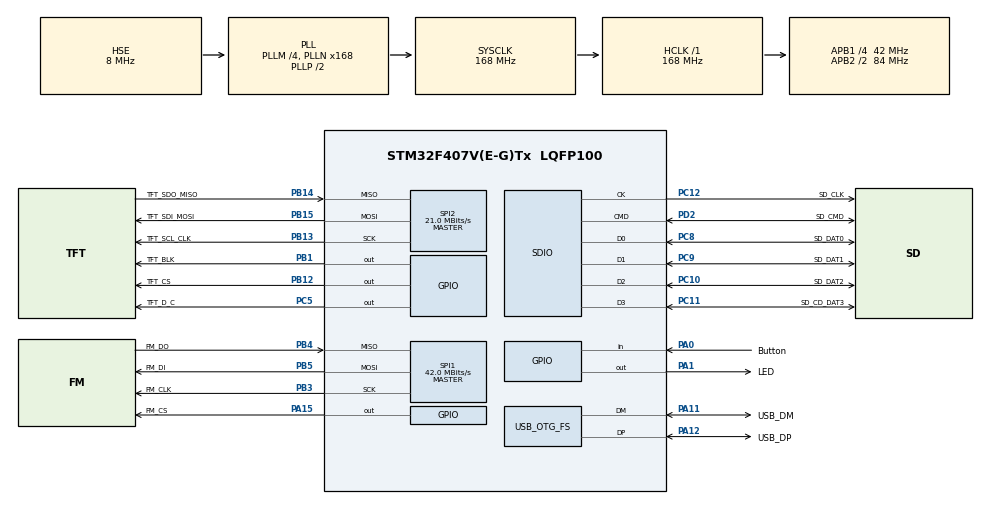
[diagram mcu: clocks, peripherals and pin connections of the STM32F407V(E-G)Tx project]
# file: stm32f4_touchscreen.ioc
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FREERTOS.Tasks01=defaultTask,24,128,StartDefaultTask,Default,NULL,Dynamic,NULL,NULL;blink_led,8,128,Blink,Default,NULL,Dynamic,NULL,NULL
FREERTOS.configUSE_NEWLIB_REENTRANT=1
Mcu.Family=STM32F4
Mcu.Name=STM32F407V(E-G)Tx
Mcu.Package=LQFP100
NVIC.OTG_FS_IRQn=true\:5\:0\:false\:false\:true\:true\:true\:true\:true
NVIC.PriorityGroup=NVIC_PRIORITYGROUP_4
NVIC.SDIO_IRQn=true\:5\:0\:false\:false\:true\:true\:true\:true\:true
PA0-WKUP.GPIO_Label=Button
PA0-WKUP.GPIO_PuPd=GPIO_PULLDOWN
PA0-WKUP.Signal=GPIO_Input
PA1.GPIO_Label=LED
PA1.GPIO_PuPd=GPIO_PULLUP
PA1.Signal=GPIO_Output
PA11.GPIO_Label=USB_DM
PA11.Mode=Device_Only
PA11.Signal=USB_OTG_FS_DM
PA12.GPIO_Label=USB_DP
PA12.Mode=Device_Only
PA12.Signal=USB_OTG_FS_DP
PA13.Mode=Serial_Wire
PA13.Signal=SYS_JTMS-SWDIO
PA14.Mode=Serial_Wire
PA14.Signal=SYS_JTCK-SWCLK
PA15.GPIO_Label=FM_CS
PA15.GPIO_PuPd=GPIO_PULLDOWN
PA15.GPIO_Speed=GPIO_SPEED_FREQ_VERY_HIGH
PA15.Signal=GPIO_Output
PB1.GPIO_Label=TFT_BLK
PB1.GPIO_PuPd=GPIO_PULLDOWN
PB1.GPIO_Speed=GPIO_SPEED_FREQ_VERY_HIGH
PB1.Signal=GPIO_Output
PB12.GPIO_Label=TFT_CS
PB12.GPIO_PuPd=GPIO_PULLDOWN
PB12.GPIO_Speed=GPIO_SPEED_FREQ_VERY_HIGH
PB12.Signal=GPIO_Output
PB13.GPIO_Label=TFT_SCL_CLK
PB13.Mode=Full_Duplex_Master
PB13.Signal=SPI2_SCK
PB14.GPIO_Label=TFT_SDO_MISO
PB14.Mode=Full_Duplex_Master
PB14.Signal=SPI2_MISO
PB15.GPIO_Label=TFT_SDI_MOSI
PB15.Mode=Full_Duplex_Master
PB15.Signal=SPI2_MOSI
PB3.GPIO_Label=FM_CLK
PB3.Mode=Full_Duplex_Master
PB3.Signal=SPI1_SCK
PB4.GPIO_Label=FM_DO
PB4.Mode=Full_Duplex_Master
PB4.Signal=SPI1_MISO
PB5.GPIO_Label=FM_DI
PB5.Mode=Full_Duplex_Master
PB5.Signal=SPI1_MOSI
PC10.GPIO_Label=SD_DAT2
PC10.Mode=SD_4_bits_Wide_bus
PC10.Signal=SDIO_D2
PC11.GPIO_Label=SD_CD_DAT3
PC11.Mode=SD_4_bits_Wide_bus
PC11.Signal=SDIO_D3
PC12.GPIO_Label=SD_CLK
PC12.Mode=SD_4_bits_Wide_bus
PC12.Signal=SDIO_CK
PC14-OSC32_IN.Mode=LSE-External-Oscillator
PC14-OSC32_IN.Signal=RCC_OSC32_IN
PC15-OSC32_OUT.Mode=LSE-External-Oscillator
PC15-OSC32_OUT.Signal=RCC_OSC32_OUT
PC5.GPIO_Label=TFT_D_C
PC5.GPIO_PuPd=GPIO_PULLDOWN
PC5.GPIO_Speed=GPIO_SPEED_FREQ_VERY_HIGH
PC5.Signal=GPIO_Output
PC8.GPIO_Label=SD_DAT0
PC8.Mode=SD_4_bits_Wide_bus
PC8.Signal=SDIO_D0
PC9.GPIO_Label=SD_DAT1
PC9.Mode=SD_4_bits_Wide_bus
PC9.Signal=SDIO_D1
PD2.GPIO_Label=SD_CMD
PD2.Mode=SD_4_bits_Wide_bus
PD2.Signal=SDIO_CMD
PH0-OSC_IN.Mode=HSE-External-Oscillator
PH0-OSC_IN.Signal=RCC_OSC_IN
PH1-OSC_OUT.Mode=HSE-External-Oscillator
PH1-OSC_OUT.Signal=RCC_OSC_OUT
ProjectManager.HeapSize=0x600
ProjectManager.StackSize=0x800
ProjectManager.TargetToolchain=STM32CubeIDE
RCC.48MHZClocksFreq_Value=48000000
RCC.AHBFreq_Value=168000000
RCC.APB1CLKDivider=RCC_HCLK_DIV4
RCC.APB1Freq_Value=42000000
RCC.APB1TimFreq_Value=84000000
RCC.APB2CLKDivider=RCC_HCLK_DIV2
RCC.APB2Freq_Value=84000000
RCC.APB2TimFreq_Value=168000000
RCC.CortexFreq_Value=168000000
RCC.HCLKFreq_Value=168000000
RCC.HSE_VALUE=8000000
RCC.HSI_VALUE=16000000
RCC.PLLM=4
RCC.PLLN=168
RCC.PLLQ=7
RCC.SYSCLKFreq_VALUE=168000000
RCC.SYSCLKSource=RCC_SYSCLKSOURCE_PLLCLK
RCC.VCOOutputFreq_Value=336000000
SPI1.CalculateBaudRate=42.0 MBits/s
SPI1.Direction=SPI_DIRECTION_2LINES
SPI1.Mode=SPI_MODE_MASTER
SPI1.VirtualType=VM_MASTER
SPI2.CalculateBaudRate=21.0 MBits/s
SPI2.Direction=SPI_DIRECTION_2LINES
SPI2.Mode=SPI_MODE_MASTER
SPI2.VirtualType=VM_MASTER
USB_DEVICE.CLASS_NAME_FS=CDC
USB_DEVICE.VirtualMode-CDC_FS=Cdc
USB_DEVICE.VirtualModeFS=Cdc_FS
USB_OTG_FS.VirtualMode=Device_Only
VP_FATFS_VS_SDIO.Mode=SDIO
VP_FREERTOS_VS_CMSIS_V2.Mode=CMSIS_V2
VP_USB_DEVICE_VS_USB_DEVICE_CDC_FS.Mode=CDC_FS
board=custom

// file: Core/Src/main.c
/* USER CODE BEGIN Header */
/**
  ******************************************************************************
  * @file           : main.c
  * @brief          : Main program body
  ******************************************************************************
  * @attention
  *
  * Copyright (c) 2023 STMicroelectronics.
  * All rights reserved.
  *
  * This software is licensed under terms that can be found in the LICENSE file
  * in the root directory of this software component.
  * If no LICENSE file comes with this software, it is provided AS-IS.
  *
  ******************************************************************************
  */
/* USER CODE END Header */
#include "main.h"
#include "cmsis_os.h"
#include "fatfs.h"
#include "usb_device.h"

/* USER CODE BEGIN Includes */
#include <stdio.h>
#include "usbd_cdc_if.h"
/* USER CODE END Includes */

SD_HandleTypeDef hsd;

SPI_HandleTypeDef hspi1;
SPI_HandleTypeDef hspi2;

/* Definitions for defaultTask */
osThreadId_t defaultTaskHandle;
const osThreadAttr_t defaultTask_attributes = {
  .name = "defaultTask",
  .stack_size = 128 * 4,
  .priority = (osPriority_t) osPriorityNormal,
};
/* Definitions for blink_led */
osThreadId_t blink_ledHandle;
const osThreadAttr_t blink_led_attributes = {
  .name = "blink_led",
  .stack_size = 128 * 4,
  .priority = (osPriority_t) osPriorityLow,
};

void SystemClock_Config(void);
static void MX_GPIO_Init(void);
static void MX_SDIO_SD_Init(void);
static void MX_SPI1_Init(void);
static void MX_SPI2_Init(void);
void StartDefaultTask(void *argument);
void Blink(void *argument);

int main(void)
{

  /* MCU Configuration--------------------------------------------------------*/

  /* Reset of all peripherals, Initializes the Flash interface and the Systick. */
  HAL_Init();

  /* Configure the system clock */
  SystemClock_Config();

  /* Initialize all configured peripherals */
  MX_GPIO_Init();
  MX_SDIO_SD_Init();
  MX_SPI1_Init();
  MX_SPI2_Init();
  MX_FATFS_Init();

  /* Init scheduler */
  osKernelInitialize();

  /* Create the thread(s) */
  /* creation of defaultTask */
  defaultTaskHandle = osThreadNew(StartDefaultTask, NULL, &defaultTask_attributes);

  /* creation of blink_led */
  blink_ledHandle = osThreadNew(Blink, NULL, &blink_led_attributes);

  /* Start scheduler */
  osKernelStart();

  /* We should never get here as control is now taken by the scheduler */
  /* Infinite loop */
  while (1)
  {

  }
}

void SystemClock_Config(void)
{
  RCC_OscInitTypeDef RCC_OscInitStruct = {0};
  RCC_ClkInitTypeDef RCC_ClkInitStruct = {0};

  /** Configure the main internal regulator output voltage
  */
  __HAL_RCC_PWR_CLK_ENABLE();
  __HAL_PWR_VOLTAGESCALING_CONFIG(PWR_REGULATOR_VOLTAGE_SCALE1);

  /** Initializes the RCC Oscillators according to the specified parameters
  * in the RCC_OscInitTypeDef structure.
  */
  RCC_OscInitStruct.OscillatorType = RCC_OSCILLATORTYPE_HSE;
  RCC_OscInitStruct.HSEState = RCC_HSE_ON;
  RCC_OscInitStruct.PLL.PLLState = RCC_PLL_ON;
  RCC_OscInitStruct.PLL.PLLSource = RCC_PLLSOURCE_HSE;
  RCC_OscInitStruct.PLL.PLLM = 4;
  RCC_OscInitStruct.PLL.PLLN = 168;
  RCC_OscInitStruct.PLL.PLLP = RCC_PLLP_DIV2;
  RCC_OscInitStruct.PLL.PLLQ = 7;
  if (HAL_RCC_OscConfig(&RCC_OscInitStruct) != HAL_OK)
  {
    Error_Handler();
  }

  /** Initializes the CPU, AHB and APB buses clocks
  */
  RCC_ClkInitStruct.ClockType = RCC_CLOCKTYPE_HCLK|RCC_CLOCKTYPE_SYSCLK
                              |RCC_CLOCKTYPE_PCLK1|RCC_CLOCKTYPE_PCLK2;
  RCC_ClkInitStruct.SYSCLKSource = RCC_SYSCLKSOURCE_PLLCLK;
  RCC_ClkInitStruct.AHBCLKDivider = RCC_SYSCLK_DIV1;
  RCC_ClkInitStruct.APB1CLKDivider = RCC_HCLK_DIV4;
  RCC_ClkInitStruct.APB2CLKDivider = RCC_HCLK_DIV2;

  if (HAL_RCC_ClockConfig(&RCC_ClkInitStruct, FLASH_LATENCY_5) != HAL_OK)
  {
    Error_Handler();
  }
}

static void MX_SDIO_SD_Init(void)
{

  hsd.Instance = SDIO;
  hsd.Init.ClockEdge = SDIO_CLOCK_EDGE_RISING;
  hsd.Init.ClockBypass = SDIO_CLOCK_BYPASS_DISABLE;
  hsd.Init.ClockPowerSave = SDIO_CLOCK_POWER_SAVE_DISABLE;
  hsd.Init.BusWide = SDIO_BUS_WIDE_4B;
  hsd.Init.HardwareFlowControl = SDIO_HARDWARE_FLOW_CONTROL_DISABLE;
  hsd.Init.ClockDiv = 0;

}

static void MX_SPI1_Init(void)
{

  /* SPI1 parameter configuration*/
  hspi1.Instance = SPI1;
  hspi1.Init.Mode = SPI_MODE_MASTER;
  hspi1.Init.Direction = SPI_DIRECTION_2LINES;
  hspi1.Init.DataSize = SPI_DATASIZE_8BIT;
  hspi1.Init.CLKPolarity = SPI_POLARITY_LOW;
  hspi1.Init.CLKPhase = SPI_PHASE_1EDGE;
  hspi1.Init.NSS = SPI_NSS_SOFT;
  hspi1.Init.BaudRatePrescaler = SPI_BAUDRATEPRESCALER_2;
  hspi1.Init.FirstBit = SPI_FIRSTBIT_MSB;
  hspi1.Init.TIMode = SPI_TIMODE_DISABLE;
  hspi1.Init.CRCCalculation = SPI_CRCCALCULATION_DISABLE;
  hspi1.Init.CRCPolynomial = 10;
  if (HAL_SPI_Init(&hspi1) != HAL_OK)
  {
    Error_Handler();
  }

}

static void MX_SPI2_Init(void)
{

  /* SPI2 parameter configuration*/
  hspi2.Instance = SPI2;
  hspi2.Init.Mode = SPI_MODE_MASTER;
  hspi2.Init.Direction = SPI_DIRECTION_2LINES;
  hspi2.Init.DataSize = SPI_DATASIZE_8BIT;
  hspi2.Init.CLKPolarity = SPI_POLARITY_LOW;
  hspi2.Init.CLKPhase = SPI_PHASE_1EDGE;
  hspi2.Init.NSS = SPI_NSS_SOFT;
  hspi2.Init.BaudRatePrescaler = SPI_BAUDRATEPRESCALER_2;
  hspi2.Init.FirstBit = SPI_FIRSTBIT_MSB;
  hspi2.Init.TIMode = SPI_TIMODE_DISABLE;
  hspi2.Init.CRCCalculation = SPI_CRCCALCULATION_DISABLE;
  hspi2.Init.CRCPolynomial = 10;
  if (HAL_SPI_Init(&hspi2) != HAL_OK)
  {
    Error_Handler();
  }

}

static void MX_GPIO_Init(void)
{
  GPIO_InitTypeDef GPIO_InitStruct = {0};

  /* GPIO Ports Clock Enable */
  __HAL_RCC_GPIOC_CLK_ENABLE();
  __HAL_RCC_GPIOH_CLK_ENABLE();
  __HAL_RCC_GPIOA_CLK_ENABLE();
  __HAL_RCC_GPIOB_CLK_ENABLE();
  __HAL_RCC_GPIOD_CLK_ENABLE();

  /*Configure GPIO pin Output Level */
  HAL_GPIO_WritePin(GPIOA, LED_Pin|FM_CS_Pin, GPIO_PIN_RESET);

  /*Configure GPIO pin Output Level */
  HAL_GPIO_WritePin(TFT_D_C_GPIO_Port, TFT_D_C_Pin, GPIO_PIN_RESET);

  /*Configure GPIO pin Output Level */
  HAL_GPIO_WritePin(GPIOB, TFT_BLK_Pin|TFT_CS_Pin, GPIO_PIN_RESET);

  /*Configure GPIO pin : Button_Pin */
  GPIO_InitStruct.Pin = Button_Pin;
  GPIO_InitStruct.Mode = GPIO_MODE_INPUT;
  GPIO_InitStruct.Pull = GPIO_PULLDOWN;
  HAL_GPIO_Init(Button_GPIO_Port, &GPIO_InitStruct);

  /*Configure GPIO pin : LED_Pin */
  GPIO_InitStruct.Pin = LED_Pin;
  GPIO_InitStruct.Mode = GPIO_MODE_OUTPUT_PP;
  GPIO_InitStruct.Pull = GPIO_PULLUP;
  GPIO_InitStruct.Speed = GPIO_SPEED_FREQ_LOW;
  HAL_GPIO_Init(LED_GPIO_Port, &GPIO_InitStruct);

  /*Configure GPIO pin : TFT_D_C_Pin */
  GPIO_InitStruct.Pin = TFT_D_C_Pin;
  GPIO_InitStruct.Mode = GPIO_MODE_OUTPUT_PP;
  GPIO_InitStruct.Pull = GPIO_PULLDOWN;
  GPIO_InitStruct.Speed = GPIO_SPEED_FREQ_VERY_HIGH;
  HAL_GPIO_Init(TFT_D_C_GPIO_Port, &GPIO_InitStruct);

  /*Configure GPIO pins : TFT_BLK_Pin TFT_CS_Pin */
  GPIO_InitStruct.Pin = TFT_BLK_Pin|TFT_CS_Pin;
  GPIO_InitStruct.Mode = GPIO_MODE_OUTPUT_PP;
  GPIO_InitStruct.Pull = GPIO_PULLDOWN;
  GPIO_InitStruct.Speed = GPIO_SPEED_FREQ_VERY_HIGH;
  HAL_GPIO_Init(GPIOB, &GPIO_InitStruct);

  /*Configure GPIO pin : FM_CS_Pin */
  GPIO_InitStruct.Pin = FM_CS_Pin;
  GPIO_InitStruct.Mode = GPIO_MODE_OUTPUT_PP;
  GPIO_InitStruct.Pull = GPIO_PULLDOWN;
  GPIO_InitStruct.Speed = GPIO_SPEED_FREQ_VERY_HIGH;
  HAL_GPIO_Init(FM_CS_GPIO_Port, &GPIO_InitStruct);

}

/* USER CODE BEGIN 4 */
int _write(int file, char *ptr, int len) {
    static uint8_t rc = USBD_OK;

    do {
        rc = CDC_Transmit_FS((uint8_t*)ptr, len);
    } while (USBD_BUSY == rc);

    if (USBD_FAIL == rc) {
        /// NOTE: Should never reach here.
        /// TODO: Handle this error.
        return 0;
    }
    return len;
}
/* USER CODE END 4 */

void StartDefaultTask(void *argument)
{
  /* init code for USB_DEVICE */
  MX_USB_DEVICE_Init();
  for(;;)
  {
    osDelay(1);
  }
}

void Blink(void *argument)
{
  /* USER CODE BEGIN Blink */
  /* Infinite loop */
  for(;;)
  {
    osDelay(1000);
    HAL_GPIO_TogglePin (LED_GPIO_Port, LED_Pin);
    printf("hello\n\r");
  }
  /* USER CODE END Blink */
}

void Error_Handler(void)
{
  __disable_irq();
  while (1)
  {
  }
}
